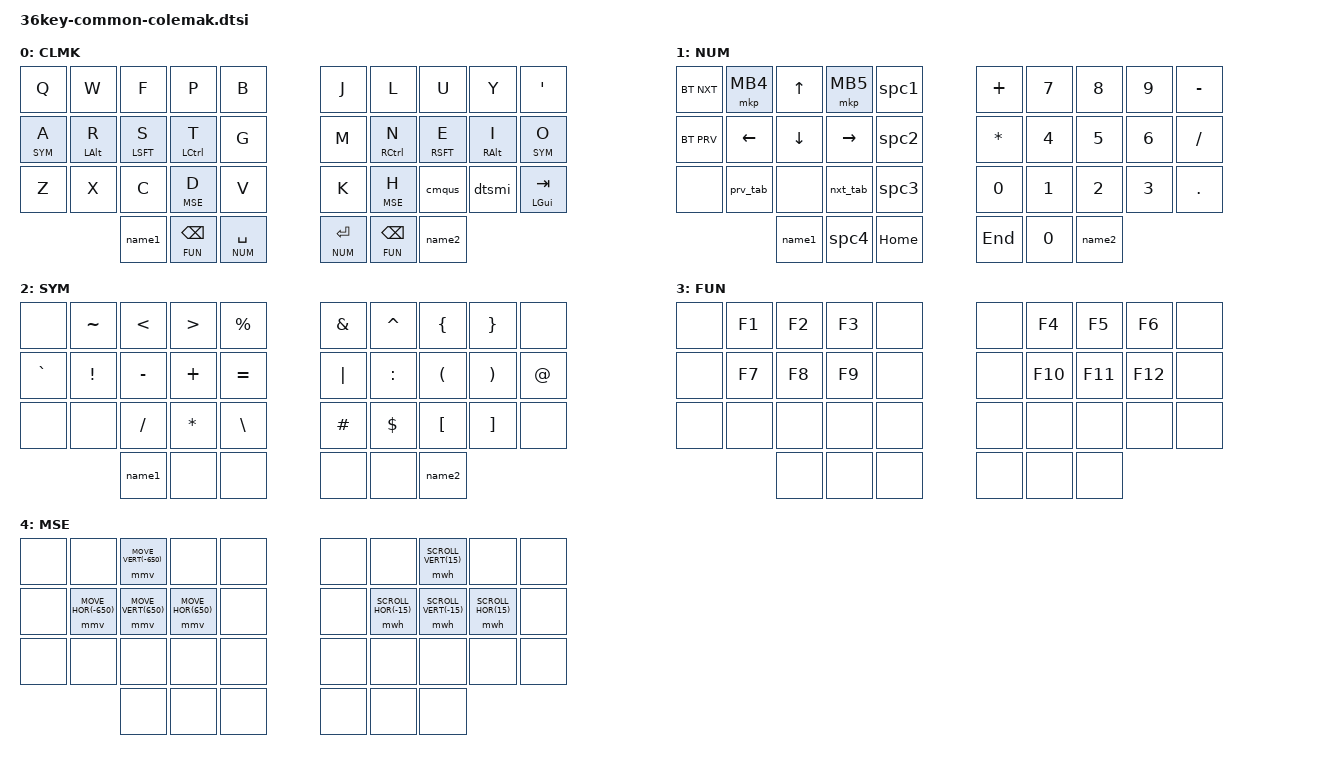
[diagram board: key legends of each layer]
#include <behaviors.dtsi>
#include <dt-bindings/zmk/keys.h>
#include <dt-bindings/zmk/bt.h>
#include <dt-bindings/zmk/outputs.h>
#include <dt-bindings/zmk/ext_power.h>
#include <dt-bindings/zmk/mouse.h>

#define DEFAULT 0
#define NUM     1
#define SYM     2
#define FUN     3
#define MSE     4

#include "key-common.dtsi"

&mt {
   flavor = "tap-preferred";
   tapping_term_ms = <200>;
};

&mmv {    
        time-to-max-speed-ms = <500>;
        acceleration-exponent=<1>;
};
&mwh {    
        time-to-max-speed-ms = <2000>;
        acceleration-exponent=<0>;
};

/ { 

    keymap {
        compatible = "zmk,keymap";
                
     		default_layer {
            label = "CLMK";
        		bindings = <
            		&kp Q &kp W      &kp F      &kp P      &kp B        &kp J     &kp L      &kp U      &kp Y      &kp SQT
             		&lt SYM A &mt LALT R &mt LSFT S &mt LCTL T &kp G    &kp M &mt RCTL N &mt RSFT E &mt RALT I &lt SYM O 
                &kp Z &kp X      &kp C      &lt MSE D      &kp V        &kp K     &lt MSE H      &cmqus     &dtsmi     &mt LGUI TAB
                          &name1 &lt FUN BSPC    &lt NUM SPACE       &lt NUM RET   &lt FUN BSPC   &name2
             		>;
            sensor-bindings = <&inc_dec_kp RIGHT LEFT &inc_dec_kp UP DOWN>;
		    };

        number_layer {
            label = "NUM";
            bindings = <
                &bt BT_NXT  &mkp MB4  &kp UP    &mkp MB5   &spc1      &kp PLUS     &kp N7 &kp N8 &kp N9 &kp MINUS
                &bt BT_PRV  &kp LEFT  &kp DOWN  &kp RIGHT  &spc2      &kp ASTRK    &kp N4 &kp N5 &kp N6 &kp FSLH
                &none       &prv_tab  &none     &nxt_tab   &spc3      &kp N0       &kp N1 &kp N2 &kp N3 &kp DOT
                                      &name1    &spc4   &kp HOME     &kp END      &kp N0  &name2
            >;
            sensor-bindings = <&inc_dec_kp PG_UP PG_DN &inc_dec_kp C_VOL_UP C_VOL_DN>;
        };

        symbol_layer {
            label = "SYM";
            bindings = <
                &none     &kp TILDE &kp LT    &kp GT   &kp PRCNT   &kp AMPS &kp CARET &kp LBRC &kp RBRC &none
                &kp GRAVE &kp EXCL  &kp MINUS &kp PLUS &kp EQUAL   &kp PIPE &kp COLON &kp LPAR &kp RPAR &kp AT
                &none     &none     &kp SLASH &kp STAR &kp BSLH    &kp HASH &kp DLLR  &kp LBKT &kp RBKT &none  
                                       &name1  &none    &none    &none    &none  &name2
            >;
                sensor-bindings = <&inc_dec_kp PG_UP PG_DN &inc_dec_kp C_VOL_UP C_VOL_DN>;
        };

        function_layer {
            label = "FUN";
            bindings = <
                &none  &kp F1  &kp F2  &kp F3  &none       &none &kp F4  &kp F5  &kp F6  &none
                &none  &kp F7  &kp F8  &kp F9  &none       &none &kp F10 &kp F11 &kp F12 &none
                &none  &none   &none   &none   &none       &none &none   &none   &none   &none
                               &none   &none   &none       &none &none   &none
            >;
                sensor-bindings = <&inc_dec_kp PG_UP PG_DN &inc_dec_kp C_VOL_UP C_VOL_DN>;
        };
        
        mouse_layer {
            label = "MSE";
            bindings = <
                &none  &none   &mmv MOVE_VERT(-650)  &none  &none                 &none  &none  &mwh SCROLL_VERT(15)  &none  &none
                &none  &mmv MOVE_HOR(-650)  &mmv MOVE_VERT(650)  &mmv MOVE_HOR(650) &none    &none  &mwh SCROLL_HOR(-15)  &mwh SCROLL_VERT(-15) &mwh SCROLL_HOR(15)  &none
                &none  &none   &none  &none  &none                        &none  &none  &none  &none  &none
                               &none   &none   &none       &none &none   &none
            >;
                sensor-bindings = <&inc_dec_kp PG_UP PG_DN &inc_dec_kp C_VOL_UP C_VOL_DN>;
        };
   	};
};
